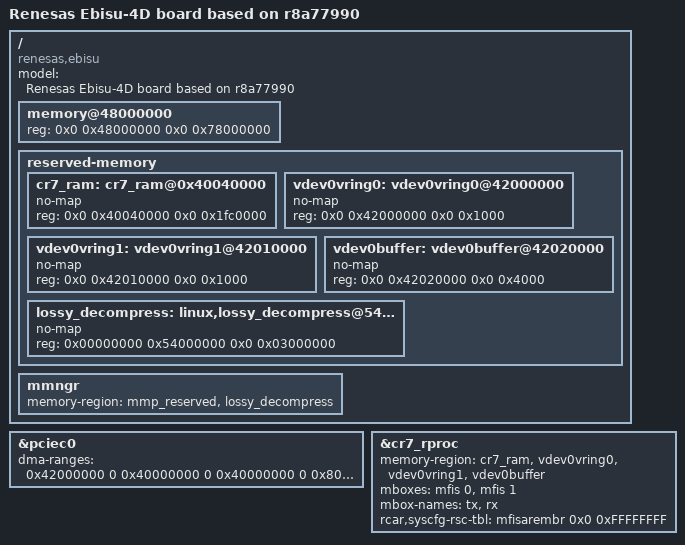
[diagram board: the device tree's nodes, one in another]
/* SPDX-License-Identifier: GPL-2.0 */
/*
 * Device Tree Source for the Ebisu-4D board
 *
 * Copyright (C) 2018 Renesas Electronics Corp.
 */

/dts-v1/;
#include "r8a77990-ebisu.dts"

/ {
	model = "Renesas Ebisu-4D board based on r8a77990";
	compatible = "renesas,ebisu", "renesas,r8a77990";

	memory@48000000 {
		device_type = "memory";
		/* first 128MB is reserved for secure area. */
		reg = <0x0 0x48000000 0x0 0x78000000>;
	};

	reserved-memory {
                #address-cells = <2>;
                #size-cells = <2>;
                ranges;

                cr7_ram: cr7_ram@0x40040000 {
                        no-map;
                        reg = <0x0 0x40040000 0x0 0x1fc0000>;
                };

                vdev0vring0: vdev0vring0@42000000 {
                        no-map;
                        reg = <0x0 0x42000000 0x0 0x1000>;
                };

                vdev0vring1: vdev0vring1@42010000 {
                        no-map;
                        reg = <0x0 0x42010000 0x0 0x1000>;
                };

                vdev0buffer: vdev0buffer@42020000 {
                        no-map;
                        reg = <0x0 0x42020000 0x0 0x4000>;
                };

		/* device specific region for Lossy Decompression */
		lossy_decompress: linux,lossy_decompress@54000000 {
			no-map;
			reg = <0x00000000 0x54000000 0x0 0x03000000>;
		};
	};

	mmngr {
		memory-region = <&mmp_reserved>, <&lossy_decompress>;
	};
};

&pciec0 {
	/* Map all possible DDR as inbound ranges */
	dma-ranges = <0x42000000 0 0x40000000 0 0x40000000 0 0x80000000>;
};

&cr7_rproc {
        memory-region = <&cr7_ram>, <&vdev0vring0>, <&vdev0vring1>, <&vdev0buffer>;
        mboxes = <&mfis 0>, <&mfis 1>;
        mbox-names = "tx", "rx";
        rcar,syscfg-rsc-tbl = <&mfisarembr 0x0 0xFFFFFFFF>;
        status = "okay";
 };
